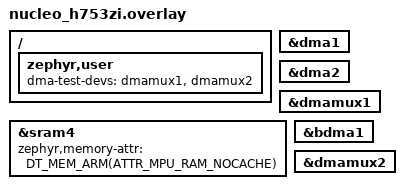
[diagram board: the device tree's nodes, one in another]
/*
 * Copyright (c) 2025 STMicroelectronics
 *
 * SPDX-License-Identifier: Apache-2.0
 */

&dma1 {
	status = "okay";
};

&dma2 {
	status = "okay";
};

&dmamux1 {
	status = "okay";
};

/* The BDMA driver expects the SRAM4 region
 * to be non-cachable.
 */
&sram4 {
	zephyr,memory-attr = <DT_MEM_ARM(ATTR_MPU_RAM_NOCACHE)>;
};

&bdma1 {
	status = "okay";
};

&dmamux2 {
	status = "okay";
};

/ {
	zephyr,user {
		dma-test-devs = <&dmamux1>, <&dmamux2>;
	};
};
